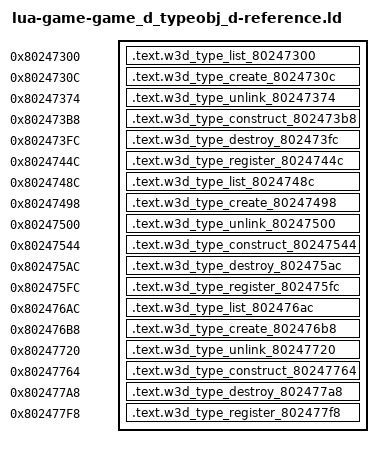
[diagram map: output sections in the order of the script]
/* Generated reference-only placements. All bodies are source-built. */
OUTPUT_FORMAT("elf32-powerpc")
OUTPUT_ARCH(powerpc)
ENTRY(w3d_type_list_80247300)
_SDA_BASE_ = 0x804b2540;
_SDA2_BASE_ = 0x804c2540;
w3d_f32_803c3cd8 = 0x803c3cd8;
w3d_object_alloc_801ea70c = 0x801ea70c;
w3d_object_base_construct_801ea0ec = 0x801ea0ec;
w3d_object_base_destroy_801ea138 = 0x801ea138;
w3d_object_free_801ea740 = 0x801ea740;
w3d_owner_list_remove = 0x8020fd2c;
w3d_script_add_link_801ebf38 = 0x801ebf38;
w3d_script_add_member_801eb674 = 0x801eb674;
w3d_script_add_prop_801ec52c = 0x801ec52c;
w3d_script_finish_type_801e8d9c = 0x801e8d9c;
w3d_script_prop_803c3c90 = 0x803c3c90;
w3d_script_prop_803c3ce8 = 0x803c3ce8;
w3d_script_prop_803c3d1c = 0x803c3d1c;
w3d_script_prop_803c3d44 = 0x803c3d44;
w3d_script_prop_803c3d6c = 0x803c3d6c;
w3d_script_prop_803c3d94 = 0x803c3d94;
w3d_script_prop_803c3dc8 = 0x803c3dc8;
w3d_script_prop_803c3df0 = 0x803c3df0;
w3d_script_prop_803c3e2c = 0x803c3e2c;
w3d_script_prop_803c3e68 = 0x803c3e68;
w3d_state_register = 0x8020fd04;
w3d_type_construct_80246f1c = 0x80246f1c;
w3d_type_destroy_80247000 = 0x80247000;
w3d_type_list_80367ba8 = 0x80367ba8;
w3d_type_list_80367bf8 = 0x80367bf8;
w3d_type_list_80367c48 = 0x80367c48;
w3d_vtable_8041b2c0 = 0x8041b2c0;
w3d_vtable_8041b2e8 = 0x8041b2e8;
w3d_vtable_8041b310 = 0x8041b310;
SECTIONS {
  .text.w3d_type_list_80247300 0x80247300 : { *(.text.w3d_type_list_80247300) }
  .text.w3d_type_create_8024730c 0x8024730c : { *(.text.w3d_type_create_8024730c) }
  .text.w3d_type_unlink_80247374 0x80247374 : { *(.text.w3d_type_unlink_80247374) }
  .text.w3d_type_construct_802473b8 0x802473b8 : { *(.text.w3d_type_construct_802473b8) }
  .text.w3d_type_destroy_802473fc 0x802473fc : { *(.text.w3d_type_destroy_802473fc) }
  .text.w3d_type_register_8024744c 0x8024744c : { *(.text.w3d_type_register_8024744c) }
  .text.w3d_type_list_8024748c 0x8024748c : { *(.text.w3d_type_list_8024748c) }
  .text.w3d_type_create_80247498 0x80247498 : { *(.text.w3d_type_create_80247498) }
  .text.w3d_type_unlink_80247500 0x80247500 : { *(.text.w3d_type_unlink_80247500) }
  .text.w3d_type_construct_80247544 0x80247544 : { *(.text.w3d_type_construct_80247544) }
  .text.w3d_type_destroy_802475ac 0x802475ac : { *(.text.w3d_type_destroy_802475ac) }
  .text.w3d_type_register_802475fc 0x802475fc : { *(.text.w3d_type_register_802475fc) }
  .text.w3d_type_list_802476ac 0x802476ac : { *(.text.w3d_type_list_802476ac) }
  .text.w3d_type_create_802476b8 0x802476b8 : { *(.text.w3d_type_create_802476b8) }
  .text.w3d_type_unlink_80247720 0x80247720 : { *(.text.w3d_type_unlink_80247720) }
  .text.w3d_type_construct_80247764 0x80247764 : { *(.text.w3d_type_construct_80247764) }
  .text.w3d_type_destroy_802477a8 0x802477a8 : { *(.text.w3d_type_destroy_802477a8) }
  .text.w3d_type_register_802477f8 0x802477f8 : { *(.text.w3d_type_register_802477f8) }
  /DISCARD/ : { *(.text*) *(.rodata*) *(.data*) *(.bss*) *(.sdata*) *(.sbss*) *(.comment) }
}
